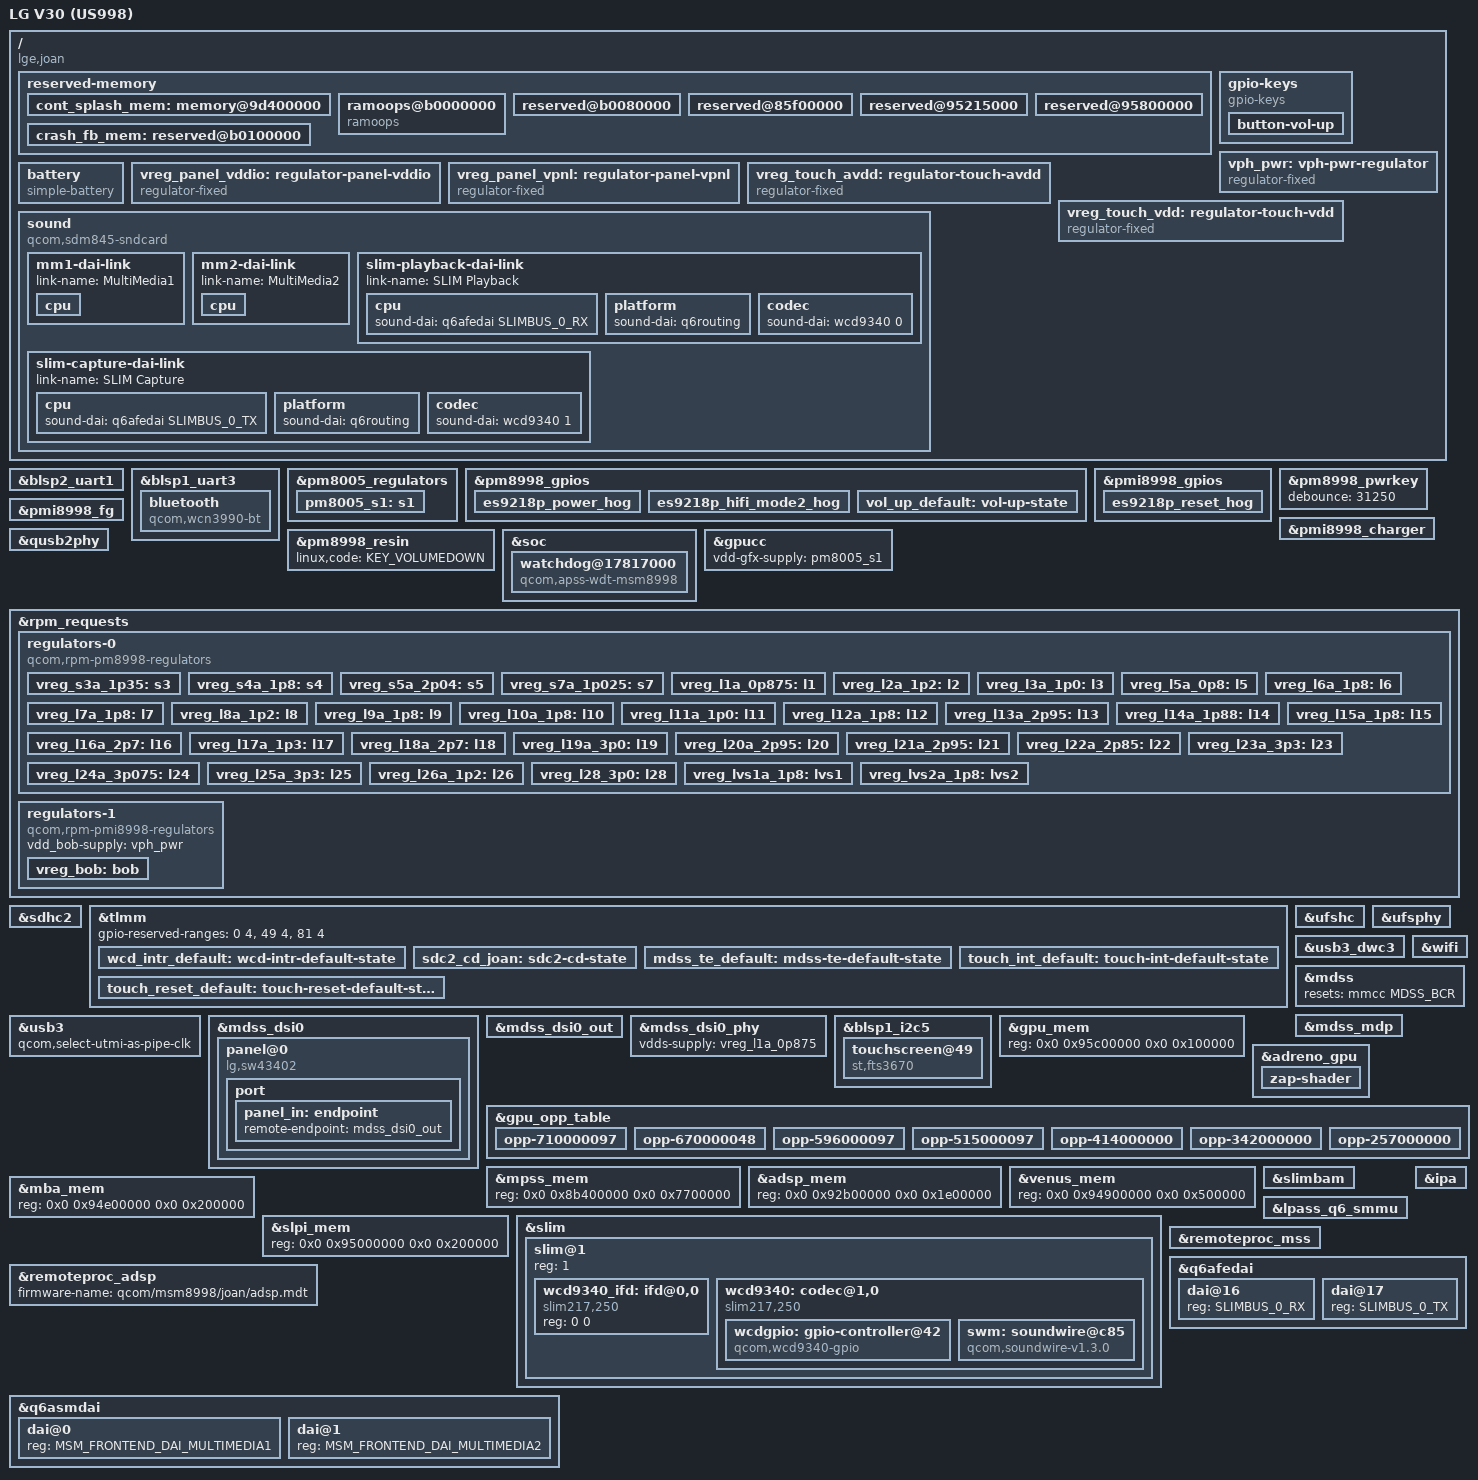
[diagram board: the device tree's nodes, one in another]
// SPDX-License-Identifier: BSD-3-Clause
/*
 * LG V30 (US998, joan) device tree source based on msm8998-oneplus-common.dtsi
 * and the downstream LG msm8998-joan device trees (LineageOS kernel/lge/msm8998).
 *
 * Copyright (c) 2026, Lance <Gero3977@gmail.com>
 */

/dts-v1/;

#include <dt-bindings/sound/qcom,q6afe.h>
#include <dt-bindings/sound/qcom,q6asm.h>
#include <dt-bindings/gpio/gpio.h>
#include <dt-bindings/input/input.h>
#include <dt-bindings/pinctrl/qcom,pmic-gpio.h>
#include "msm8998.dtsi"
#include "pm8005.dtsi"
#include "pm8998.dtsi"
#include "pmi8998.dtsi"

/ {
	model = "LG V30 (US998)";
	compatible = "lge,joan", "qcom,msm8998";
	chassis-type = "handset";

	/* Required for bootloader to select correct board */
	qcom,msm-id = <292 0x20001>; /* 8998 v2.1 */
	/*
	 * LG aboot matches the appended DTB against the unit's hardware
	 * revision. Downstream ships one DTB per rev (rev_a .. rev_1_3);
	 * list every US998 (joan_nao_us) board id so a single DTB matches
	 * any revision. Trim to the real rev once read from the device.
	 */
	qcom,board-id = <0x308 0>, <0x608 0>, <0x708 0>,
			<0x808 0>, <0x908 0>, <0xa08 0>,
			<0xc08 0>, <0xd08 0>, <0xe08 0>,
			<0xf08 0>;

	/*
	 * No chosen/simple-framebuffer node: the SW43402 panel runs DSI
	 * command mode with DSC, so the splash image persists in panel
	 * GRAM but CPU writes to the splash buffer are never scanned out
	 * again after the bootloader stops kicking off frames. A simplefb
	 * console would be silently invisible; USB gadget + ramoops are
	 * the bring-up debug channels instead.
	 */

	reserved-memory {
		/* Bootloader display framebuffer region, same as downstream */
		cont_splash_mem: memory@9d400000 {
			reg = <0x0 0x9d400000 0x0 0x2400000>;
			no-map;
		};

		/*
		 * Byte-compatible with the downstream ramoops layout
		 * (msm8998-joan_*.dtsi: mem-size 0x80000, console @0,
		 * ftrace @0x40000, no dump/pmsg space): after a crashed
		 * mainline boot falls back to the LG 4.4 kernel, Android
		 * parses our console log and drops it in
		 * /data/system/dropbox as SYSTEM_LAST_KMSG. Any other
		 * split leaves the log invisible to downstream.
		 */
		ramoops@b0000000 {
			compatible = "ramoops";
			reg = <0x0 0xb0000000 0x0 0x80000>;
			record-size = <0x1000>;
			console-size = <0x40000>;
			ftrace-size = <0x40000>;
		};

		/* rest of downstream's 1 MiB ramoops carve-out */
		reserved@b0080000 {
			reg = <0x0 0xb0080000 0x0 0x80000>;
			no-map;
		};

		/*
		 * LG's firmware memory map (downstream msm8998.dtsi +
		 * joan dtsi) protects more RAM than mainline msm8998.dtsi
		 * reserves. These nodes plug exactly the holes where the
		 * mainline allocator could hand out firmware-owned pages
		 * (instant silent XPU reset). Deltas: tail of LG's
		 * removed_regions, tail of pil_slpi (LG SLPI ends at
		 * 0x95c00000, not 0x95200000) split around mainline's
		 * gpu_mem/wlan_msa nodes, pil_ipa_gpu, and LG's crash_fb.
		 * Note mainline gpu_mem/wlan_msa (0x95600000/0x95700000)
		 * lie inside LG's SLPI range and must move before zap
		 * shader / wifi bringup.
		 */
		reserved@85f00000 {
			reg = <0x0 0x85f00000 0x0 0x100000>;
			no-map;
		};

		reserved@95215000 {
			/*
			 * Extended to 0x95700000 so it also covers mainline's
			 * default gpu_mem spot (0x95600000), which lies inside
			 * LG's SLPI range; gpu_mem moves to LG's pil_ipa_gpu
			 * address below.
			 */
			reg = <0x0 0x95215000 0x0 0x4eb000>;
			no-map;
		};

		reserved@95800000 {
			/* Ends at 0x95c00000: LG's pil_ipa_gpu starts there. */
			reg = <0x0 0x95800000 0x0 0x400000>;
			no-map;
		};

		crash_fb_mem: reserved@b0100000 {
			reg = <0x0 0xb0100000 0x0 0x1800000>;
			no-map;
		};
	};

	gpio-keys {
		compatible = "gpio-keys";
		label = "Volume up";

		pinctrl-names = "default";
		pinctrl-0 = <&vol_up_default>;

		button-vol-up {
			label = "Volume up";
			gpios = <&pm8998_gpios 6 GPIO_ACTIVE_LOW>;
			linux,code = <KEY_VOLUMEUP>;
			debounce-interval = <15>;
			wakeup-source;
		};
	};

	vph_pwr: vph-pwr-regulator {
		compatible = "regulator-fixed";
		regulator-name = "vph_pwr";
		regulator-always-on;
		regulator-boot-on;
	};
};

&blsp2_uart1 {
	status = "okay";
};

&blsp1_uart3 {
	status = "okay";
	assigned-clocks = <&gcc GCC_BLSP1_UART3_APPS_CLK>;
	assigned-clock-rates = <48000000>;

	bluetooth {
		compatible = "qcom,wcn3990-bt";
		firmware-name = "crnv21.bin";
		vddio-supply = <&vreg_s3a_1p35>;
		vddxo-supply = <&vreg_s5a_2p04>;
		vddrf-supply = <&vreg_l17a_1p3>;
		vddch0-supply = <&vreg_l25a_3p3>;
		max-speed = <3000000>;

		/*
		 * joan has no factory BD address: the NVM's address TLV is
		 * all zeroes and the vendor stack generates a random address
		 * on first use. The all-zero placeholder is rejected by the
		 * core, which leaves the controller HCI_UNCONFIGURED so that
		 * userspace can supply one (MGMT_OP_SET_PUBLIC_ADDRESS).
		 */
		local-bd-address = [ 00 00 00 00 00 00 ];
	};
};

&pm8005_regulators {
	/* VDD_GFX supply; managed by the OPP framework + msm_gpu (vdd) */
	pm8005_s1: s1 {
		regulator-min-microvolt = <524000>;
		regulator-max-microvolt = <1100000>;
		regulator-enable-ramp-delay = <500>;
		/*
		 * No always-on: the GPU_GX GDSC now owns this rail via
		 * vdd-gfx-supply, so it is enabled and disabled together with
		 * the GX domain. Holding it on unconditionally kept VDD_GFX
		 * powered even with the GPU idle.
		 */
	};
};

&pm8998_gpios {
	/*
	 * ES9218P "Quad DAC" mode pins.  joan's headphone jack is wired
	 * through the ES9218P, not straight off the WCD9340, so the jack is
	 * dead unless the DAC is in a mode that passes audio.  LG's
	 * es9218p.c documents the pin encoding:
	 *
	 *   reset=H && hifi_mode2=L  -> HiFi mode
	 *   reset=L && hifi_mode2=H  -> Low Power Bypass   <- this
	 *   reset=L && hifi_mode2=L  -> Standby / shutdown
	 *   reset=H && hifi_mode2=H  -> LowFi mode
	 *
	 * Low Power Bypass routes the WCD9340's own analog HPHL/HPHR to the
	 * jack, which is what we want until the ES9218P driver owns these
	 * pins and can run the standby -> LPB -> HiFi sequence itself.  The
	 * chip still needs its supply up for the bypass switch to conduct,
	 * hence power high.
	 *
	 * DT numbering here is 1-based: pinctrl-spmi-gpio's of_xlate
	 * subtracts PMIC_GPIO_PHYSICAL_OFFSET, so <10> is PMIC GPIO_10 and
	 * matches downstream's numbers directly.
	 */
	es9218p_power_hog {
		gpio-hog;
		gpios = <10 GPIO_ACTIVE_HIGH>;
		output-high;
		line-name = "es9218p-power";
	};

	es9218p_hifi_mode2_hog {
		gpio-hog;
		gpios = <12 GPIO_ACTIVE_HIGH>;
		output-high;
		line-name = "es9218p-hifi-mode2";
	};

	vol_up_default: vol-up-state {
		pins = "gpio6";
		function = "normal";
		bias-pull-up;
		input-enable;
		qcom,drive-strength = <PMIC_GPIO_STRENGTH_NO>;
	};
};

&pmi8998_gpios {
	/* ES9218P RESETb held low: see the mode table on &pm8998_gpios. */
	es9218p_reset_hog {
		gpio-hog;
		gpios = <2 GPIO_ACTIVE_HIGH>;
		output-low;
		line-name = "es9218p-reset-n";
	};
};

&pm8998_pwrkey {
	/*
	 * joan's power switch chatters. A single press produces extra
	 * press/release pairs with hold times as short as 3 ms, and the gaps
	 * between them measure 17-19 ms -- just wide enough to clear the
	 * 15.625 ms debounce inherited from pm8998.dtsi. The stray edge
	 * arrives while the screen is blanking, so the display locks and
	 * immediately wakes again as though the key had been pressed twice.
	 *
	 * Use the value the vendor ships for this PMIC: downstream's
	 * msm-pm8998.dtsi sets qcom,pon-dbc-delay = <31250>, twice the
	 * generic mainline figure, and the observed chatter falls in the
	 * window between the two. Hold-to-power-off is measured in seconds
	 * and is unaffected.
	 */
	debounce = <31250>;
};

&pm8998_resin {
	linux,code = <KEY_VOLUMEDOWN>;
	status = "okay";
};

&pmi8998_charger {
	qcom,usb-icl-ua = <1800000>;
	qcom,fcc-max-ua = <3300000>;
	monitored-battery = <&battery>;
	status = "okay";
};

&pmi8998_fg {
	power-supplies = <&pmi8998_charger>;
	monitored-battery = <&battery>;
	status = "okay";
};

/ {
	battery: battery {
		compatible = "simple-battery";
		voltage-min-design-microvolt = <3200000>;
		voltage-max-design-microvolt = <4400000>;
		charge-full-design-microamp-hours = <3312000>;
	};
};

&soc {
	/*
	 * APSS watchdog, missing from mainline msm8998.dtsi (address
	 * from downstream qcom,wdt@17817000). LG's boot chain leaves
	 * it armed, so a kernel that never pets it resets ~30s in
	 * even when otherwise healthy.
	 */
	watchdog@17817000 {
		compatible = "qcom,apss-wdt-msm8998", "qcom,kpss-wdt";
		reg = <0x17817000 0x1000>;
		clocks = <&sleep_clk>;
	};
};

&gpucc {
	/* The GX GDSC gates VDD_GFX with the GPU's own power domain. */
	vdd-gfx-supply = <&pm8005_s1>;
};

&qusb2phy {
	status = "okay";

	vdd-supply = <&vreg_l1a_0p875>;
	vdda-pll-supply = <&vreg_l12a_1p8>;
	vdda-phy-dpdm-supply = <&vreg_l24a_3p075>;
};

&rpm_requests {
	/*
	 * Rail voltages copied from msm8998-oneplus-common (standard 8998
	 * MTP wiring). Cross-check against downstream
	 * msm8998-joan-common-pm.dtsi before enabling more peripherals.
	 */
	regulators-0 {
		compatible = "qcom,rpm-pm8998-regulators";

		vdd_s1-supply = <&vph_pwr>;
		vdd_s2-supply = <&vph_pwr>;
		vdd_s3-supply = <&vph_pwr>;
		vdd_s4-supply = <&vph_pwr>;
		vdd_s5-supply = <&vph_pwr>;
		vdd_s6-supply = <&vph_pwr>;
		vdd_s7-supply = <&vph_pwr>;
		vdd_s8-supply = <&vph_pwr>;
		vdd_s9-supply = <&vph_pwr>;
		vdd_s10-supply = <&vph_pwr>;
		vdd_s11-supply = <&vph_pwr>;
		vdd_s12-supply = <&vph_pwr>;
		vdd_s13-supply = <&vph_pwr>;
		vdd_l1_l27-supply = <&vreg_s7a_1p025>;
		vdd_l2_l8_l17-supply = <&vreg_s3a_1p35>;
		vdd_l3_l11-supply = <&vreg_s7a_1p025>;
		vdd_l4_l5-supply = <&vreg_s7a_1p025>;
		vdd_l6-supply = <&vreg_s5a_2p04>;
		vdd_l7_l12_l14_l15-supply = <&vreg_s5a_2p04>;
		vdd_l9-supply = <&vreg_bob>;
		vdd_l10_l23_l25-supply = <&vreg_bob>;
		vdd_l13_l19_l21-supply = <&vreg_bob>;
		vdd_l16_l28-supply = <&vreg_bob>;
		vdd_l18_l22-supply = <&vreg_bob>;
		vdd_l20_l24-supply = <&vreg_bob>;
		vdd_l26-supply = <&vreg_s3a_1p35>;
		vdd_lvs1_lvs2-supply = <&vreg_s4a_1p8>;

		vreg_s3a_1p35: s3 {
			regulator-min-microvolt = <1352000>;
			regulator-max-microvolt = <1352000>;
		};

		vreg_s4a_1p8: s4 {
			regulator-min-microvolt = <1800000>;
			regulator-max-microvolt = <1800000>;
			regulator-allow-set-load;
		};

		vreg_s5a_2p04: s5 {
			regulator-min-microvolt = <1904000>;
			regulator-max-microvolt = <2040000>;
		};

		vreg_s7a_1p025: s7 {
			regulator-min-microvolt = <900000>;
			regulator-max-microvolt = <1028000>;
		};

		vreg_l1a_0p875: l1 {
			regulator-min-microvolt = <880000>;
			regulator-max-microvolt = <880000>;
		};

		vreg_l2a_1p2: l2 {
			regulator-min-microvolt = <1200000>;
			regulator-max-microvolt = <1200000>;
		};

		vreg_l3a_1p0: l3 {
			regulator-min-microvolt = <1000000>;
			regulator-max-microvolt = <1000000>;
		};

		vreg_l5a_0p8: l5 {
			regulator-min-microvolt = <800000>;
			regulator-max-microvolt = <800000>;
		};

		vreg_l6a_1p8: l6 {
			regulator-min-microvolt = <1808000>;
			regulator-max-microvolt = <1808000>;
		};

		vreg_l7a_1p8: l7 {
			regulator-min-microvolt = <1800000>;
			regulator-max-microvolt = <1800000>;
		};

		vreg_l8a_1p2: l8 {
			regulator-min-microvolt = <1200000>;
			regulator-max-microvolt = <1200000>;
		};

		vreg_l9a_1p8: l9 {
			regulator-min-microvolt = <1808000>;
			regulator-max-microvolt = <2960000>;
		};

		vreg_l10a_1p8: l10 {
			regulator-min-microvolt = <1808000>;
			regulator-max-microvolt = <2960000>;
		};

		vreg_l11a_1p0: l11 {
			regulator-min-microvolt = <1000000>;
			regulator-max-microvolt = <1000000>;
		};

		vreg_l12a_1p8: l12 {
			regulator-min-microvolt = <1800000>;
			regulator-max-microvolt = <1800000>;
		};

		vreg_l13a_2p95: l13 {
			regulator-min-microvolt = <1808000>;
			regulator-max-microvolt = <2960000>;
		};

		vreg_l14a_1p88: l14 {
			regulator-min-microvolt = <1880000>;
			regulator-max-microvolt = <1880000>;
		};

		vreg_l15a_1p8: l15 {
			regulator-min-microvolt = <1800000>;
			regulator-max-microvolt = <1800000>;
		};

		vreg_l16a_2p7: l16 {
			regulator-min-microvolt = <2704000>;
			regulator-max-microvolt = <2704000>;
		};

		vreg_l17a_1p3: l17 {
			regulator-min-microvolt = <1304000>;
			regulator-max-microvolt = <1304000>;
		};

		vreg_l18a_2p7: l18 {
			regulator-min-microvolt = <2704000>;
			regulator-max-microvolt = <2704000>;
		};

		vreg_l19a_3p0: l19 {
			regulator-min-microvolt = <3008000>;
			regulator-max-microvolt = <3008000>;
		};

		vreg_l20a_2p95: l20 {
			regulator-min-microvolt = <2960000>;
			regulator-max-microvolt = <2960000>;
			regulator-allow-set-load;
		};

		vreg_l21a_2p95: l21 {
			regulator-min-microvolt = <2960000>;
			regulator-max-microvolt = <2960000>;
			regulator-system-load = <800000>;
			regulator-allow-set-load;
		};

		vreg_l22a_2p85: l22 {
			regulator-min-microvolt = <2864000>;
			regulator-max-microvolt = <2864000>;
		};

		vreg_l23a_3p3: l23 {
			regulator-min-microvolt = <3312000>;
			regulator-max-microvolt = <3312000>;
		};

		vreg_l24a_3p075: l24 {
			regulator-min-microvolt = <3088000>;
			regulator-max-microvolt = <3088000>;
		};

		vreg_l25a_3p3: l25 {
			regulator-min-microvolt = <3104000>;
			regulator-max-microvolt = <3312000>;
		};

		vreg_l26a_1p2: l26 {
			regulator-min-microvolt = <1200000>;
			regulator-max-microvolt = <1200000>;
			regulator-allow-set-load;
		};

		vreg_l28_3p0: l28 {
			regulator-min-microvolt = <3008000>;
			regulator-max-microvolt = <3008000>;
		};

		vreg_lvs1a_1p8: lvs1 { };
		vreg_lvs2a_1p8: lvs2 { };
	};

	regulators-1 {
		compatible = "qcom,rpm-pmi8998-regulators";

		vdd_bob-supply = <&vph_pwr>;

		vreg_bob: bob {
			regulator-min-microvolt = <3312000>;
			regulator-max-microvolt = <3600000>;
		};
	};
};

&sdhc2 {
	status = "okay";

	cd-gpios = <&tlmm 40 GPIO_ACTIVE_LOW>;

	vmmc-supply = <&vreg_l21a_2p95>;
	vqmmc-supply = <&vreg_l13a_2p95>;

	pinctrl-names = "default", "sleep";
	pinctrl-0 = <&sdc2_on &sdc2_cd_joan>;
	pinctrl-1 = <&sdc2_off &sdc2_cd_joan>;
};

&tlmm {
	gpio-reserved-ranges = <0 4>, <49 4>, <81 4>;

	wcd_intr_default: wcd-intr-default-state {
		pins = "gpio54";
		function = "gpio";
		bias-pull-down;
		drive-strength = <2>;
	};


	/*
	 * The SoC-level sdc2_cd state uses the MTP's GPIO 95; joan routes
	 * SD card-detect to GPIO 40 (downstream msm8998-joan_*.dtsi,
	 * cd-gpios = <&tlmm 40 0x1>).
	 */
	sdc2_cd_joan: sdc2-cd-state {
		pins = "gpio40";
		function = "gpio";
		bias-pull-up;
		drive-strength = <2>;
	};

	/*
	 * Panel tear-effect input. Downstream routes the SW43402's TE
	 * output to TLMM GPIO 10 muxed as mdp_vsync_a
	 * (msm8998-joan-common-pinctrl.dtsi, mdss_te_active) and leaves
	 * MDP_VSYNC_SEL at its reset default, i.e. vsync source 0
	 * ("mdp_vsync_p" in mainline terms).
	 */
	mdss_te_default: mdss-te-default-state {
		pins = "gpio10";
		function = "mdp_vsync_a";
		drive-strength = <2>;
		bias-pull-down;
	};

	touch_int_default: touch-int-default-state {
		pins = "gpio125";
		function = "gpio";
		drive-strength = <2>;
		bias-pull-up;
	};

	touch_reset_default: touch-reset-default-state {
		pins = "gpio89";
		function = "gpio";
		drive-strength = <2>;
		bias-pull-up;
	};
};

&ufshc {
	status = "okay";

	vcc-supply = <&vreg_l20a_2p95>;
	vccq-supply = <&vreg_l26a_1p2>;
	vccq2-supply = <&vreg_s4a_1p8>;
	vdd-hba-supply = <&vreg_l26a_1p2>;
	vcc-max-microamp = <750000>;
	vccq-max-microamp = <560000>;
	vccq2-max-microamp = <750000>;
};

&ufsphy {
	status = "okay";

	vdda-phy-supply = <&vreg_l1a_0p875>;
	vdda-pll-supply = <&vreg_l2a_1p2>;
};

&usb3 {
	status = "okay";

	/* Run USB 2 only -- see the note on usb3_dwc3 below. */
	qcom,select-utmi-as-pipe-clk;
};

&usb3_dwc3 {
	/*
	 * USB 2, peripheral only. The SuperSpeed + dr_mode="otg" +
	 * usb-role-switch variant was tried on device 2026-08-16 with
	 * CONFIG_PHY_QCOM_QMP_USB=y and it produced NO USB AT ALL: the kernel
	 * boots (fastboot returns, pmOS runs) but no gadget ever enumerates.
	 * So the modular-PHY theory is dead -- the DT change itself is what
	 * breaks it. Most likely dr_mode="otg" + usb-role-switch with no
	 * role-switch provider on this SoC: dwc3 registers the switch, nothing
	 * ever sets a role, and the gadget never starts.
	 *
	 * Next experiment should be dr_mode="host" (no role provider needed)
	 * to isolate whether the USB3 PHY itself is fine, and it must be
	 * tested ALONE -- bundling it with the adsp_mem change cost a boot
	 * and made the result unattributable.
	 */
	phys = <&qusb2phy>;
	phy-names = "usb2-phy";
	maximum-speed = "high-speed";
	dr_mode = "peripheral";
};

&wifi {
	vdd-0.8-cx-mx-supply = <&vreg_l5a_0p8>;
	vdd-1.8-xo-supply = <&vreg_l7a_1p8>;
	vdd-1.3-rfa-supply = <&vreg_l17a_1p3>;
	vdd-3.3-ch0-supply = <&vreg_l25a_3p3>;
	status = "okay";
};

/*
 * Display: SW43402 DSC command-mode panel.
 * Validated on device — the panel lights up and GPU rendering works. The
 * mmss SMMU (cd00000.iommu) deferred-probe -110 that once blocked this
 * chain is resolved; see the MDSS BCR reset note below for the remaining
 * bootloader-handoff workaround.
 * Panel rails are board GPIO-enabled fixed supplies (downstream uses
 * lge,gpio-vddio = TLMM 92, lge,gpio-vpnl = TLMM 69).
 */
/ {
	vreg_panel_vddio: regulator-panel-vddio {
		compatible = "regulator-fixed";
		regulator-name = "panel_vddio";
		regulator-min-microvolt = <1800000>;
		regulator-max-microvolt = <1800000>;
		gpio = <&tlmm 92 GPIO_ACTIVE_HIGH>;
		enable-active-high;
		regulator-boot-on;
	};

	vreg_panel_vpnl: regulator-panel-vpnl {
		compatible = "regulator-fixed";
		regulator-name = "panel_vpnl";
		regulator-min-microvolt = <3000000>;
		regulator-max-microvolt = <3000000>;
		gpio = <&tlmm 69 GPIO_ACTIVE_HIGH>;
		enable-active-high;
		regulator-boot-on;
	};
};

&mdss {
	status = "okay";
	/*
	 * Hard-reset the whole MDSS complex at probe: the bootloader
	 * leaves the display pipeline live (splash/fastboot screen), and
	 * programming the first modeset onto running hardware wedges the
	 * HS pixel path until a full disable/enable cycle. The BCR pulse
	 * gives the kernel cold silicon instead.
	 */
	resets = <&mmcc MDSS_BCR>;
};

&mdss_mdp {
	status = "okay";
};

&mdss_dsi0 {
	vdd-supply = <&vreg_l1a_0p875>;
	vdda-supply = <&vreg_l2a_1p2>;
	status = "okay";

	panel@0 {
		compatible = "lg,sw43402";
		reg = <0>;

		vddio-supply = <&vreg_panel_vddio>;
		vpnl-supply = <&vreg_panel_vpnl>;

		reset-gpios = <&tlmm 35 GPIO_ACTIVE_LOW>;

		pinctrl-0 = <&mdss_te_default>;
		pinctrl-names = "default";

		port {
			panel_in: endpoint {
				remote-endpoint = <&mdss_dsi0_out>;
			};
		};
	};
};

&mdss_dsi0_out {
	data-lanes = <0 1 2 3>;
	remote-endpoint = <&panel_in>;
	qcom,te-source = "mdp_vsync_p";
};

&mdss_dsi0_phy {
	vdds-supply = <&vreg_l1a_0p875>;
	status = "okay";
};

/*
 * Touch: STMicro FingerTipS on blsp1_i2c5 at 0x49. Downstream binds its
 * own "stm,ftm4" driver (lge_touch); mainline's stmfts speaks the same
 * FingerTipS command set, so try it first. The controller keeps its
 * firmware in on-chip flash — downstream only pushes L0S59P1_1_11.ftb
 * for updates — so no firmware file is needed to bring it up.
 *
 * Both rails are GPIO load switches, not programmable regulators, so
 * the voltages below are nominal descriptors only. Downstream names
 * them vdd-gpio (TLMM 85) and vio-gpio (TLMM 86); the mapping onto
 * stmfts's "avdd" (analog) and "vdd" (digital I/O) is inferred from the
 * usual FingerTipS wiring and is unverified on this board.
 */
/ {
	vreg_touch_avdd: regulator-touch-avdd {
		compatible = "regulator-fixed";
		regulator-name = "touch_avdd";
		regulator-min-microvolt = <3300000>;
		regulator-max-microvolt = <3300000>;
		gpio = <&tlmm 85 GPIO_ACTIVE_HIGH>;
		enable-active-high;
	};

	vreg_touch_vdd: regulator-touch-vdd {
		compatible = "regulator-fixed";
		regulator-name = "touch_vdd";
		regulator-min-microvolt = <1800000>;
		regulator-max-microvolt = <1800000>;
		gpio = <&tlmm 86 GPIO_ACTIVE_HIGH>;
		enable-active-high;
	};
};

&blsp1_i2c5 {
	status = "okay";

	touchscreen@49 {
		compatible = "st,fts3670";
		reg = <0x49>;

		interrupt-parent = <&tlmm>;
		interrupts = <125 IRQ_TYPE_LEVEL_LOW>;

		vdd-supply = <&vreg_touch_vdd>;
		avdd-supply = <&vreg_touch_avdd>;

		reset-gpios = <&tlmm 89 GPIO_ACTIVE_LOW>;

		touchscreen-size-x = <1440>;
		touchscreen-size-y = <2880>;

		pinctrl-names = "default";
		pinctrl-0 = <&touch_int_default &touch_reset_default>;
	};
};

/*
 * GPU (Adreno 540).
 *
 * gpu_mem moves to 0x95c00000, matching LG's pil_ipa_gpu region. This is
 * required because mainline's default 0x95600000 lies inside LG's SLPI
 * carve-out (0x94d00000-0x95c00000): letting the allocator hand out
 * firmware-owned pages there causes an immediate silent XPU reset. The
 * a540 zap blob itself is RELOCATABLE (QCOM_MDT_RELOCATABLE), so it does
 * not require any particular address -- an earlier comment claiming it was
 * address-locked was wrong; the move is about LG's memory map, not the blob.
 *
 * A540 reuses the redistributable A530 PM4/PFP command firmware supplied by
 * linux-firmware. The A540 GPMU and signed LG ZAP payload remain
 * owner-extracted, device-specific inputs. All four firmware roles must be
 * available under qcom/ in the firmware search path (the initramfs for the
 * early-probe images used here).
 */
&gpu_mem {
	reg = <0x0 0x95c00000 0x0 0x100000>;
};

&adreno_gpu {
	status = "okay";

	/*
	 * msm8998.dtsi points power-domains at the RPM VDDMX voltage domain,
	 * which drives opp-level but does NOT switch the GPU on. The binding
	 * allows a single power-domain, and every other Adreno 5xx in tree
	 * (e.g. msm8996: power-domains = <&mmcc GPU_GX_GDSC>) attaches the GX
	 * GDSC instead. With the RPM domain in that slot the GPUCC gpu_gx /
	 * gpu_cx GDSCs have no consumer, never power up, and the clocks that
	 * depend on them never produce a rate -- so the first register write
	 * lands on an unpowered, unclocked block and hangs the AHB bus.
	 * gpu_gx is a child of gpu_cx, so enabling GX brings CX up with it.
	 */
	power-domains = <&gpucc GPU_GX_GDSC>;

	vdd-supply = <&pm8005_s1>;

	zap-shader {
		memory-region = <&gpu_mem>;
		firmware-name = "qcom/a540_zap.mdt";
	};
};

/*
 * GPU OPP levels and voltages.
 *
 * msm_gpu's enable_clk() sets the core clock to gpu->fast_rate -- the
 * HIGHEST OPP -- as part of every resume, before any register access.
 * The original bring-up capped the table at 257 MHz (MIN_SVS) because
 * VDD_GFX (pm8005_s1) sat at the boot voltage (~752 mV) with no scaling
 * in place, and turbo on a low-SVS voltage is not survivable.
 *
 * The stock Android kernel was swept on this exact device (2026-08-04;
 * pm8005_s1 readback per kgsl pwrlevel) and the measured curve is used
 * here as opp-microvolt. adreno_get_pwrlevels() registers the vdd
 * supply with the OPP framework, so every dev_pm_opp_set_rate() scales
 * the rail BEFORE raising the core clock; the resume fast_rate jump is
 * therefore exactly the stock turbo corner (710 MHz @ 936 mV), which
 * the device runs routinely. opp-level is intentionally omitted: the
 * GPU's power domain is the GPU_GX GDSC (see above), which has no
 * performance states.
 */
&gpu_opp_table {
	/delete-node/ opp-710000097;
	/delete-node/ opp-670000048;
	/delete-node/ opp-596000097;
	/delete-node/ opp-515000097;
	/delete-node/ opp-414000000;
	/delete-node/ opp-342000000;
	/delete-node/ opp-257000000;

	/*
	 * EXPERIMENTAL overclock OPP (local-only, never upstream):
	 * 750 MHz is a Qualcomm-shipped GPU rate for this SoC family
	 * (downstream clock-gpu-8998.c carries a 180-750 MHz table for
	 * higher-binned parts; the V30 bin ships the 710 MHz table).
	 * Voltage: the first device test used 965 mV, which the OPP core
	 * REJECTED ("OPP not supported by regulators") because the
	 * pm8005_s1 rail (SPMI ftsmps426) steps in 4 mV — 965000 is
	 * off-grid. 964000 is on-grid (964/4=241) and matches the linear
	 * extrapolation of the measured curve (936 mV @ 710 MHz,
	 * ~0.7 mV/MHz -> ~964 mV @ 750 MHz), under the 1.1 V rail max.
	 * This OPP becomes fast_rate, so every GPU resume runs the 750
	 * corner. If the PLL cannot lock at the higher VCO, GPU probe
	 * fails or renders hang - RAM-only and fully reversible (revert
	 * this commit).
	 */

	/*
	 * EXPERIMENTAL sweep OPPs above the device-proven 750 MHz corner
	 * (G5-OC2 PASS). Frequencies beyond 750 are NOT Qualcomm-validated
	 * for this SoC family — this is true overclocking past the
	 * shipped envelope, tested empirically. Voltages are on-grid
	 * (4 mV step) extrapolations of the measured curve (~0.7 mV/MHz
	 * above 964 mV @ 750 MHz): 800 -> 1000 mV, 850 -> 1036 mV,
	 * 900 -> 1072 mV (rail max 1100 mV).
	 *
	 * CAUTION: the highest OPP becomes fast_rate, so every GPU
	 * resume runs the TOP corner. 900 MHz was device-tested
	 * (G6-OC-RX) and REJECTED: the PLL cannot lock at the ~5.4 GHz
	 * VCO during probe ("gpupll0 failed to enable!" twice in
	 * clk-alpha-pll wait_for_pll), which wedges the GPU/DRM device
	 * for the whole session. Since msm always runs fast_rate on
	 * resume, 900 is unusable as a corner and is dropped; 850 MHz
	 * is now the top corner and the empirical ceiling question.
	 */


	opp-710000097 {
		opp-hz = /bits/ 64 <710000097>;
		opp-microvolt = <936000>;
		opp-supported-hw = <0xff>;
	};

	opp-670000048 {
		opp-hz = /bits/ 64 <670000048>;
		opp-microvolt = <908000>;
		opp-supported-hw = <0xff>;
	};

	opp-596000097 {
		opp-hz = /bits/ 64 <596000097>;
		opp-microvolt = <856000>;
		opp-supported-hw = <0xff>;
	};

	opp-515000097 {
		opp-hz = /bits/ 64 <515000097>;
		opp-microvolt = <792000>;
		opp-supported-hw = <0xff>;
	};

	opp-414000000 {
		opp-hz = /bits/ 64 <414000000>;
		opp-microvolt = <704000>;
		opp-supported-hw = <0xff>;
	};

	opp-342000000 {
		opp-hz = /bits/ 64 <342000000>;
		opp-microvolt = <644000>;
		opp-supported-hw = <0xff>;
	};

	opp-257000000 {
		opp-hz = /bits/ 64 <257000000>;
		opp-microvolt = <628000>;
		opp-supported-hw = <0xff>;
	};
};

/*
 * Modem (MSS) bring-up.
 *
 * LG's firmware is signed for its own physical addresses and the MBA
 * authenticates the modem image in place, so the regions the modem
 * chain touches are transcribed from the vendor kernel's
 * reserved-memory node rather than chosen. The generic msm8998.dtsi
 * layout is a different packing of the same DDR and does not match:
 *
 *   region      mainline generic        LG stock
 *   mpss_mem    0x8cc00000 + 0x7000000  0x8b400000 + 0x7700000
 *   adsp_mem    0x8b200000 + 0x1a00000  0x92b00000 + 0x1b00000
 *   mba_mem     0x94100000 + 0x200000   0x94b00000 + 0x200000
 *   venus_mem   0x93c00000 + 0x500000   0x94600000 + 0x500000
 *
 * Note the generic adsp_mem at 0x8b200000 lies inside the range LG
 * gives the modem (0x8b400000-0x92afffff), so the layout cannot be
 * changed one region at a time -- it moves as a chain.
 *
 * slpi_mem is the exception. LG gives SLPI 0x94d00000 + 0xf00000, but
 * that range covers ipa_fw_mem, ipa_gsi_mem and wlan_msa_mem, which sit
 * at their mainline addresses and are working: WiFi is up on those and
 * the GPU zap shader already uses LG's 0x95c00000 for gpu_mem. SLPI
 * itself is not enabled here, so it is given only the 5 MB it needs to
 * clear adsp_mem rather than LG's full extent. Revisit if SLPI is ever
 * brought up -- and note IPA will need its own look, since LG lumps IPA
 * and GPU firmware into one 1 MB pil_ipa_gpu_mem at 0x95c00000.
 */
&mpss_mem {
	reg = <0x0 0x8b400000 0x0 0x7700000>;
};

&adsp_mem {
	/*
	 * 30 MB, matching joan's own downstream override
	 * (msm8998-joan-common-pm.dtsi), not the generic msm8998 27 MB that
	 * was here before.
	 *
	 * joan's adsp.mdt needs exactly 0x1e00000 of relocatable PT_LOAD span
	 * (0x91900000..0x93700000; the 0x93700000 QCOM_MDT_TYPE_HASH phdr is
	 * excluded). mainline mdt_loader.c and downstream pil_setup_region()
	 * compute the same figure, and mdt_loader rejects on
	 * `offset + p_memsz > mem_size` regardless of relocation -- so at 27 MB
	 * the ADSP dies with "segment outside memory range" / rproc start -22.
	 *
	 * LG moves the chain with it. adsp/video/mba below are LG's values
	 * verbatim. slpi deliberately is NOT: LG gives it 0xf00000 running to
	 * 0x95f00000, which would swallow mainline's ipa_fw_mem, ipa_gsi_mem
	 * and wlan_msa_mem. Following the existing design note above, SLPI is
	 * not enabled here, so it keeps only enough to clear adsp and stops at
	 * 0x95200000 where ipa_fw_mem begins. Everything from 0x95200000 up --
	 * ipa, wlan_msa, gpu_mem and the reserved@ plug nodes -- is therefore
	 * untouched and keeps working.
	 *
	 * UNTESTED ON DEVICE. An earlier attempt at this layout booted to no
	 * USB, but that image also enabled the USB3 PHY in DT while
	 * CONFIG_PHY_QCOM_QMP_USB was =m, so dwc3 deferred forever on a PHY
	 * that cannot load on a RAM boot. There is no evidence the layout
	 * itself is at fault. Test it with PHY_QCOM_QMP_USB=y, and change one
	 * thing at a time.
	 */
	reg = <0x0 0x92b00000 0x0 0x1e00000>;
};

&venus_mem {
	/* LG joan pil_video_mem */
	reg = <0x0 0x94900000 0x0 0x500000>;
};

&mba_mem {
	/* LG joan pil_mba_mem */
	reg = <0x0 0x94e00000 0x0 0x200000>;
};

&slpi_mem {
	/*
	 * 2 MB, stopping at ipa_fw_mem. LG's own value is 0xf00000 to
	 * 0x95f00000, but that range holds mainline's ipa/wlan_msa/gpu
	 * nodes, which work and must not move. SLPI is not enabled.
	 */
	reg = <0x0 0x95000000 0x0 0x200000>;
};

/*
 * SLIMbus. The NGD is managed by the ADSP, so this can only work once
 * remoteproc adsp is running (device-verified 2026-08-16). Enabling it here
 * to see whether the NGD probes; the WCD934x codec node is a separate step.
 */
&slimbam {
	status = "okay";
};

&slim {
	status = "okay";

	/*
	 * WCD9340 (tavil). Downstream declares it as qcom,tavil-slim-pgd with
	 * elemental-addr [00 01 50 02 17 02] -- manufacturer 0x217, product
	 * 0x250 -- which is exactly mainline's "slim217,250", so the sdm845
	 * node shape applies directly.
	 *
	 * joan specifics taken from downstream msm8998-audio.dtsi:
	 *   interrupt  tlmm 54   (wcd9xxx_intc: qcom,gpio-connect = <&tlmm 54 0>)
	 *   mclk       LN_BB from the PMIC (clock_audio_lnbb / wcd_clk); on
	 *              msm8998 that is rpmcc RPM_SMD_LN_BB_CLK1, which is in the
	 *              msm8998 rpm clk table and already used elsewhere here.
	 *
	 * NOT probed yet. Requires the ADSP running (it manages the NGD).
	 */
	slim@1 {
		reg = <1>;
		#address-cells = <2>;
		#size-cells = <0>;

		wcd9340_ifd: ifd@0,0 {
			compatible = "slim217,250";
			reg = <0 0>;
		};

		wcd9340: codec@1,0 {
			compatible = "slim217,250";
			reg = <1 0>;
			slim-ifc-dev = <&wcd9340_ifd>;

			/*
			 * All five rails come off PM8998 S4 at 1.8 V. Downstream
			 * feeds cdc-vdd-buck / cdc-buck-sido / cdc-vdd-tx-h /
			 * cdc-vdd-rx-h / cdc-vddpx-1 all from <&pm8998_s4> at
			 * 1800000, which is vreg_s4a_1p8 here. Without these the
			 * codec runs on dummy regulators and SLIMbus logical-address
			 * assignment fails ("Failed to get logical address").
			 */
			vdd-buck-supply = <&vreg_s4a_1p8>;
			vdd-buck-sido-supply = <&vreg_s4a_1p8>;
			vdd-tx-supply = <&vreg_s4a_1p8>;
			vdd-rx-supply = <&vreg_s4a_1p8>;
			vdd-io-supply = <&vreg_s4a_1p8>;

			#sound-dai-cells = <1>;

			interrupts-extended = <&tlmm 54 IRQ_TYPE_LEVEL_HIGH>;
			interrupt-controller;
			#interrupt-cells = <1>;

			/*
			 * Codec reset. Downstream: wcd_rst_gpio msm_cdc_pinctrl@64
			 * with qcom,cdc-rst-n-gpio = <&tlmm 64 0>. The mainline
			 * wcd934x mfd takes this as an optional "reset" gpio and
			 * asserts it before SLIMbus enumeration.
			 */
			reset-gpios = <&tlmm 64 GPIO_ACTIVE_HIGH>;

			clock-names = "extclk";
			clocks = <&rpmcc RPM_SMD_LN_BB_CLK1>;

			#clock-cells = <0>;
			clock-frequency = <9600000>;
			clock-output-names = "mclk";

			pinctrl-0 = <&wcd_intr_default>;
			pinctrl-names = "default";

			qcom,micbias1-microvolt = <1800000>;
			qcom,micbias2-microvolt = <1800000>;
			qcom,micbias3-microvolt = <1800000>;
			qcom,micbias4-microvolt = <1800000>;

			#address-cells = <1>;
			#size-cells = <1>;

			wcdgpio: gpio-controller@42 {
				compatible = "qcom,wcd9340-gpio";
				gpio-controller;
				#gpio-cells = <2>;
				reg = <0x42 0x2>;
			};

			/*
			 * The WCD934x MFD instantiates a soundwire child
			 * unconditionally; without this node it fails with
			 * "wcd934x-soundwire: Failed to locate of_node [id: -2]".
			 * Port layout is the codec's own and is identical to the
			 * sdm845 shared dtsi -- it describes the WCD934x internal
			 * link, not anything board-specific. joan drives its
			 * loudspeaker via a TFA98xx on I2C rather than WSA parts on
			 * this bus, so no slave devices are declared here.
			 */
			swm: soundwire@c85 {
				compatible = "qcom,soundwire-v1.3.0";
				reg = <0xc85 0x40>;
				interrupts-extended = <&wcd9340 20>;

				qcom,dout-ports = <6>;
				qcom,din-ports = <2>;
				qcom,ports-sinterval-low = /bits/ 8 <0x07 0x1f 0x3f 0x7 0x1f 0x3f 0x0f 0x0f>;
				qcom,ports-offset1 = /bits/ 8 <0x01 0x02 0x0c 0x6 0x12 0x0d 0x07 0x0a>;
				qcom,ports-offset2 = /bits/ 8 <0x00 0x00 0x1f 0x00 0x00 0x1f 0x00 0x00>;

				#sound-dai-cells = <1>;
				clocks = <&wcd9340>;
				clock-names = "iface";
				#address-cells = <2>;
				#size-cells = <0>;
			};
		};
	};
};

&remoteproc_adsp {
	firmware-name = "qcom/msm8998/joan/adsp.mdt";
	status = "okay";
};

/*
 * The ADSP's own IOMMU.  q6asmdai (msm8998.dtsi) takes its audio context
 * bank from here, so the PCM buffer handed to the DSP is an IOVA the Q6 can
 * translate rather than a bare physical address.
 */
&lpass_q6_smmu {
	status = "okay";
};

&remoteproc_mss {
	firmware-name = "qcom/msm8998/joan/mba.mbn",
			"qcom/msm8998/joan/modem.mdt";
	status = "okay";
};

/*
 * IPA. Needed by ModemManager: it reads the QMI bus over QRTR fine but
 * will not instantiate a modem without IPA's rmnet/wwan netdevs
 * (pmaports !3531 reports the same on OnePlus 5/5T). The modem itself
 * works without this -- it boots, authenticates and advertises its full
 * QMI service set -- but nothing consumes it.
 */
&ipa {
	memory-region = <&ipa_fw_mem>;
	qcom,gsi-loader = "self";
	status = "okay";
};

/*
 * Minimal sound card for first light. Playback and capture over SLIMBUS_0 to
 * the WCD9340, plus one MultiMedia frontend each way -- enough to create an
 * ALSA card and prove the q6 <-> codec path, not a full topology.
 *
 * compatible is "qcom,sdm845-sndcard" deliberately. sound/soc/qcom/sdm845.c
 * implements exactly this topology (q6 frontends + wcd934x over SLIMbus) and
 * its match table says "Do not grow the list for compatible devices", which is
 * why db845c and yoga-c630 reuse it too. joan has the same codec and the same
 * DAI shape. If msm8998 later needs behaviour sdm845.c does not provide, this
 * is the thing to revisit.
 *
 * NOT YET PROBED.
 */
/ {
	sound {
		compatible = "qcom,sdm845-sndcard";
		model = "LG-V30";
		status = "okay";

		/*
		 * "Left Spk"/"SPK1 OUT" was copied from db845c, which drives
		 * WSA881x amps off the codec's SoundWire speaker output.  joan
		 * has no WSA parts -- its loudspeaker is a TFA98xx on i2c_7 --
		 * so that route named a widget nothing declares.  Dropped.
		 *
		 * The codec's own analog outputs (EAR, HPHL, HPHR) are
		 * SND_SOC_DAPM_OUTPUT endpoints and need no board route to be
		 * usable; they are reached by the RX INTn chain kcontrols.
		 */
		audio-routing =
			"RX_BIAS", "MCLK",
			"AMIC1", "MIC BIAS1",
			"AMIC2", "MIC BIAS2",
			"AMIC3", "MIC BIAS3";

		mm1-dai-link {
			link-name = "MultiMedia1";
			cpu {
				sound-dai = <&q6asmdai MSM_FRONTEND_DAI_MULTIMEDIA1>;
			};
		};

		mm2-dai-link {
			link-name = "MultiMedia2";
			cpu {
				sound-dai = <&q6asmdai MSM_FRONTEND_DAI_MULTIMEDIA2>;
			};
		};

		slim-playback-dai-link {
			link-name = "SLIM Playback";
			cpu {
				sound-dai = <&q6afedai SLIMBUS_0_RX>;
			};

			platform {
				sound-dai = <&q6routing>;
			};

			codec {
				sound-dai = <&wcd9340 0>;
			};
		};

		slim-capture-dai-link {
			link-name = "SLIM Capture";
			cpu {
				sound-dai = <&q6afedai SLIMBUS_0_TX>;
			};

			platform {
				sound-dai = <&q6routing>;
			};

			codec {
				sound-dai = <&wcd9340 1>;
			};
		};
	};
};

/*
 * q6asm/q6afe DAI children. Both drivers count child nodes at probe --
 * q6asm-dai fails with "No dais found in DT" / -EINVAL without them -- so the
 * frontends and backends actually in use have to be declared here.
 */
&q6asmdai {
	dai@0 {
		reg = <MSM_FRONTEND_DAI_MULTIMEDIA1>;
	};

	dai@1 {
		reg = <MSM_FRONTEND_DAI_MULTIMEDIA2>;
	};
};

&q6afedai {
	dai@16 {
		reg = <SLIMBUS_0_RX>;
	};

	dai@17 {
		reg = <SLIMBUS_0_TX>;
	};
};
